AUTOSAR XML (schema 4-2-2)
package /IoHwAb_PWM
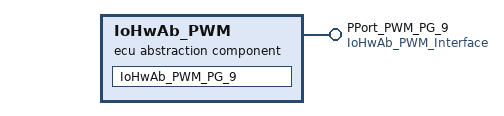
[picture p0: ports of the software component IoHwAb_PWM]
  ecu abstraction sw component type IoHwAb_PWM
    provide port PPort_PWM_PG_9: provided-interface=IoHwAb_PWM_Interface
    behavior IB_IoHwAb_PWM
      operation invoked event OperationInvokedEvent_0: start-on-event=IoHwAb_PWM_PG_9, operation=PPort_PWM_PG_9.IoHwAb_PWM_Set
      runnable IoHwAb_PWM_PG_9: symbol=IoHwAb_PWM_PG_9_func
